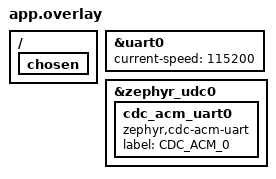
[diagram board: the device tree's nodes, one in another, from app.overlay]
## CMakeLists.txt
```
cmake_minimum_required(VERSION 3.20.0)
find_package(Zephyr REQUIRED HINTS $ENV{ZEPHYR_BASE})
project(nordic_clean)

# Dołączamy nasze pliki źródłowe
target_sources(app PRIVATE 
    src/main.c 
    src/protocol.c
    src/uart_serializer.c
)
```

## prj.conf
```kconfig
CONFIG_GPIO=y
CONFIG_HEAP_MEM_POOL_SIZE=16384
CONFIG_DK_LIBRARY=y

# === Serial & UART ===
CONFIG_SERIAL=y
CONFIG_UART_INTERRUPT_DRIVEN=y
# Wyłączamy Async API na sztywno, żeby uniknąć konfliktów
CONFIG_UART_ASYNC_API=n

# === USB Device Stack ===
CONFIG_USB_DEVICE_STACK=y
CONFIG_USB_DEVICE_PRODUCT="nRF UART3"
CONFIG_USB_DEVICE_VID=0x1915
CONFIG_USB_DEVICE_PID=0x520F
# Ręczna inicjalizacja w main()
CONFIG_USB_DEVICE_INITIALIZE_AT_BOOT=n

# === USB CDC ACM (Kluczowe dla drugiego portu) ===
CONFIG_USB_CDC_ACM=y
CONFIG_UART_LINE_CTRL=y

# === Logowanie (Tylko RTT) ===
CONFIG_LOG=y
CONFIG_USE_SEGGER_RTT=y
CONFIG_LOG_BACKEND_RTT=y
CONFIG_LOG_BACKEND_UART=n
# Wyłączamy konsolę na UART, żeby nie blokowała portu
CONFIG_UART_CONSOLE=n
CONFIG_CONSOLE=y
```

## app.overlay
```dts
/* nordic/app.overlay */
/ {
	chosen {
		/* Usuwamy konsolę z UART0, żeby zwolnić go dla danych */
		/delete-property/ zephyr,console;
		/delete-property/ zephyr,shell-uart;
		/delete-property/ zephyr,uart-mcumgr;
	};
};

/* UART0 - Dane/Ethernet (Górny port J-Link) */
&uart0 {
	status = "okay";
	current-speed = <115200>;
};

/* USB CDC - Konsola Użytkownika (Boczny port nRF USB) */
&zephyr_udc0 {
	cdc_acm_uart0: cdc_acm_uart0 {
		compatible = "zephyr,cdc-acm-uart";
		label = "CDC_ACM_0";
	};
};
```

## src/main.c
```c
#include <zephyr/kernel.h>
#include <zephyr/drivers/uart.h>
#include <zephyr/usb/usb_device.h>
#include <zephyr/logging/log.h>
#include <dk_buttons_and_leds.h>
#include <string.h>
#include "uart_serializer.h" // Tutaj mamy definicje kodów i unpack_header
#include "protocol.h"        // Tutaj mamy definicje InterfaceType

LOG_MODULE_REGISTER(app, LOG_LEVEL_INF);

#define BUF_SIZE 256
#define MSGQ_SIZE 10

// === DEFINICJA STRUKTURY WIADOMOŚCI ===
// Musi być widoczna przed definicją kolejki!
typedef struct {
    uint8_t *data;        // Wskaźnik do dynamicznie alokowanego bufora
    size_t len;           // Długość danych
    InterfaceType source; // Skąd przyszło? (IF_CLI lub IF_UART3)
} PacketMsg;

// UART0 (Górny port) -> DANE (Protokół Binarny)
const struct device *uart_data = DEVICE_DT_GET(DT_NODELABEL(uart0));

// USB CDC (Boczny port) -> KONSOLA (Tekst)
const struct device *uart_cli = DEVICE_DT_GET(DT_NODELABEL(cdc_acm_uart0));

// Definicja kolejki z użyciem naprawionej struktury
K_MSGQ_DEFINE(main_msgq, sizeof(PacketMsg), MSGQ_SIZE, 4);

// Bufor dla Konsoli (Tekst)
static char cli_line_buf[BUF_SIZE];
static int  cli_line_pos = 0;

// === ISR: Konsola (USB - Tekst) ===
static void cli_isr(const struct device *dev, void *user_data) {
    uint8_t c;
    uart_irq_update(dev);
    if (uart_irq_rx_ready(dev)) {
        while (uart_fifo_read(dev, &c, 1) == 1) {
            uart_poll_out(dev, c); // Echo
            if (c == '\n' || c == '\r') {
                if (cli_line_pos > 0) {
                    cli_line_buf[cli_line_pos] = '\0';
                    size_t len;
                    // Serializacja tekstu do binarki
                    uint8_t* pkt = serialize_command_alloc(cli_line_buf, &len);
                    if (pkt) {
                        PacketMsg msg = { .data = pkt, .len = len, .source = IF_CLI };
                        k_msgq_put(&main_msgq, &msg, K_NO_WAIT);
                    } else {
                        uart_poll_out(dev, '?'); uart_poll_out(dev, '\n');
                    }
                    cli_line_pos = 0;
                }
                uart_poll_out(dev, '\r'); uart_poll_out(dev, '\n');
            } else {
                if (cli_line_pos < BUF_SIZE - 1) cli_line_buf[cli_line_pos++] = c;
            }
        }
    }
}
// === ISR: DANE (UART0 - Binarny) ===
static void data_isr(const struct device *dev, void *user_data) {
    uint8_t c;
    
    // Bufor strumieniowy
    static uint8_t rx_buf[256];
    static int rx_pos = 0;
    static uint16_t total_frame_len = 0; // Ile bajtów łącznie musimy uzbierać (Header + Payload)

    uart_irq_update(dev);

    if (uart_irq_rx_ready(dev)) {
        while (uart_fifo_read(dev, &c, 1) == 1) {
            
            // 1. Zbieramy dane do bufora
            if (rx_pos < sizeof(rx_buf)) {
                rx_buf[rx_pos++] = c;
            } else {
                // Przepełnienie - reset
                rx_pos = 0; 
                total_frame_len = 0;
            }

            // 2. Analiza nagłówka (gdy mamy pierwsze 4 bajty)
            if (total_frame_len == 0 && rx_pos >= 4) {
                uint16_t payload_len_from_header;
                uint16_t func_code;
                
                // Odczytujemy to co jest w nagłówku (np. 8)
                unpack_header(rx_buf, &payload_len_from_header, &func_code);
                
                // === KLUCZOWA POPRAWKA ===
                // Protokół mówi: Wartość w nagłówku to PAYLOAD.
                // Więc całkowita długość ramki to: PAYLOAD + 4 BAJTY NAGŁÓWKA.
                total_frame_len = payload_len_from_header + 4;
                
                // Walidacja (czy nie za duże na nasz bufor)
                if (total_frame_len > sizeof(rx_buf) || total_frame_len < 4) {
                    rx_pos = 0; 
                    total_frame_len = 0;
                }
            }

            // 3. Czy mamy całą ramkę?
            if (total_frame_len > 0 && rx_pos >= total_frame_len) {
                // Mamy komplet! (np. 12 bajtów: 4 header + 8 payload)
                
                uint8_t* pkt_copy = k_malloc(total_frame_len);
                if (pkt_copy) {
                    memcpy(pkt_copy, rx_buf, total_frame_len);
                    
                    PacketMsg msg = { 
                        .data = pkt_copy, 
                        .len = total_frame_len, // Przekazujemy CAŁĄ długość ramki
                        .source = IF_UART3 
                    };
                    k_msgq_put(&main_msgq, &msg, K_NO_WAIT);
                }

                // Obsługa sklejonych ramek (jeśli przyszło coś więcej niż ta jedna ramka)
                if (rx_pos > total_frame_len) {
                    int leftover = rx_pos - total_frame_len;
                    memmove(rx_buf, &rx_buf[total_frame_len], leftover);
                    rx_pos = leftover;
                } else {
                    rx_pos = 0;
                }
                total_frame_len = 0; // Reset, czekamy na nowy nagłówek
            }
        }
    }
}

int main(void) {
    k_msleep(100);
    dk_leds_init();

    if (usb_enable(NULL) != 0) { return -1; }
    k_msleep(1000); 

    if (!device_is_ready(uart_data) || !device_is_ready(uart_cli)) return -1;

    // Konfiguracja przerwań
    uart_irq_callback_user_data_set(uart_cli, cli_isr, NULL);
    uart_irq_rx_enable(uart_cli);
    uart_line_ctrl_set(uart_cli, UART_LINE_CTRL_DTR, 1);

    uart_irq_callback_user_data_set(uart_data, data_isr, NULL);
    uart_irq_rx_enable(uart_data);

    LOG_INF("SYSTEM READY");
    LOG_INF(" - CLI (Text/Cmd): USB CDC");
    LOG_INF(" - DATA (Binary): UART0");

    PacketMsg msg;
    for (;;) {
        if (k_msgq_get(&main_msgq, &msg, K_FOREVER) == 0) {
            dk_set_led(DK_LED1, 1);

            if (msg.source == IF_UART3) { 
                // Przyszło z SIECI (UART0)
                uint16_t payload_len, func;
                
                // unpack_header odczyta z bajtów wartość "8"
                unpack_header(msg.data, &payload_len, &func);
                
                LOG_INF("RECV FRAME: HeaderVal=%d, TotalRx=%d, Func=0x%03X", 
                        (int)payload_len, (int)msg.len, func);
                
                // Wypisujemy Payload
                // msg.len to całkowita długość (Header+Payload), np. 12
                // Odejmujemy 4 bajty nagłówka, zostaje 8 bajtów danych.
                size_t actual_payload_len = msg.len - 4;

                if (actual_payload_len > 0) {
                    uint8_t *payload_ptr = msg.data + 4; // Przesuwamy wskaźnik za nagłówek

                    // HEX DUMP
                    LOG_HEXDUMP_INF(payload_ptr, actual_payload_len, "Payload (HEX)");

                    // // STRING VIEW
                    // char txt_buf[129];
                    // size_t print_len = (actual_payload_len < 128) ? actual_payload_len : 128;
                    // memcpy(txt_buf, payload_ptr, print_len);
                    // txt_buf[print_len] = '\0';
                    // LOG_INF("Payload (Str): %s", txt_buf);
                }

                // Echo dla debugu na konsolę CLI
                uart_poll_out(uart_cli, '[');
                uart_poll_out(uart_cli, 'R');
                uart_poll_out(uart_cli, 'X');
                uart_poll_out(uart_cli, ']');
                uart_poll_out(uart_cli, '\r');
                uart_poll_out(uart_cli, '\n');

            } else {
                // Przyszło z KONSOLI -> WYSYŁAMY DO SIECI
                // Uwaga: Tutaj serialize_command_alloc musi też być zgodny z tą logiką!
                // W obecnej wersji serialize_command_alloc wpisuje TOTAL size. 
                // Jeśli chcesz być w 100% zgodny, musisz w uart_serializer.c zmienić:
                // pack_header(..., (uint16_t)payload_size, ...); zamiast total_size.
                
                for(int i=0; i<msg.len; i++) uart_poll_out(uart_data, msg.data[i]);
                LOG_INF("CMD -> NET (%d bytes)", (int)msg.len);
            }

            if (msg.data) k_free(msg.data);
            dk_set_led(DK_LED1, 0);
        }
    }
}
```

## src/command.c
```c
#include "command.h"

void pack_header(uint8_t* buffer, uint16_t length, uint16_t func_code, uint8_t flags) {
    buffer[0] = (length >> 4) & 0xFF;
    buffer[1] = ((length & 0x0F) << 4) | ((func_code >> 8) & 0x0F);
    buffer[2] = func_code & 0xFF;
    buffer[3] = flags;
}

int unpack_header(const uint8_t * buffer, uint16_t * len, uint16_t * func_code, uint8_t * flags)
{
  if(!buffer || !(len || func_code || flags ) ) return -1;
  
  if(len) *len = (uint16_t)(buffer[0]<<4) | (buffer[1] >> 4);
  if(func_code) *func_code = (uint16_t)( (buffer[1] & 0x0F) << 8) | (buffer[2]);
  if(flags) *flags = buffer[3];
  return 0;
}

int parse_line(char *line, Command *cmd) {
    if (line == NULL || cmd == NULL) {
        return 0;
    }

    // 1. Oblicz długość danych
    int len = strlen(line) + 1; // +1 dla null-terminatora

    // 2. Zaalokuj pamięć używając Twojego slab_alloc
    char *payload = (char*)slab_malloc(len);
    
    if (payload == NULL) {
        return 0; // Brak pamięci!
    }

    // 3. Skopiuj dane do nowej pamięci
    strcpy(payload, line);

    // 4. Wypełnij strukturę Command
    cmd->data_ptr = payload;
    cmd->interface = IF_UART; // Oznaczamy, że przyszło z UART

    return 1; // Sukces
}
```

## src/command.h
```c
#ifndef __COMMAND_H
#define __COMMAND_H

#include <stdint.h>
#include <stddef.h>
#include <string.h>
#include "slab_alloc.h"

//source definitions
#define IF_INTERNAL    0x01
#define IF_UART        0x02
#define IF_ETH         0x04
//#define IF_P2P         0x08
//#define IF_BROAD_INNER 0x7F // nearest neighbor broadcast; UART user, P2P and server
//#define IF_BROAD_OUTER 0xFF // every single node in the web, including UART


// --- Command Definitions (Same as before) ---
#define CAT_SYSTEM    0x1
#define CAT_SIM       0x2
#define CAT_SIM_API   0x3
#define CAT_SIM_NOTIF 0xE
#define CAT_SYS_NOTIF 0xF





/*
  
 OUTPUTS  

*/


// System commands
#define SYS_PING     0x01 //payload: str(ip)
#define SYS_CONN     0x02 //payload: str(ip)
#define SYS_DISCONN  0x03 //payload: None
#define SYS_RAW_SEND 0x04 //payload: str(any)



// System Notifications (0xF)
#define SYS_NOTIF_UNKNOWN 0x01 //payload: None
#define SYS_NOTIF_DEBUG   0x02 //payload: str(any)
#define SYS_NOTIF_FORBID  0x03 //payload: None
#define SYS_NOTIF_OK      0x04 //payload: None

// Simulation Notifications (0xE)
#define NOTIF_SIM_ALERT   0x01 // Code Payload
#define NOTIF_SIM_LOG     0x02 // String Payload







typedef struct {
  uint8_t interface; //source or target, depending on where it is fed
  uint8_t * data_ptr; //typically a pointer to a slab
} Command;



void pack_header(uint8_t* buffer, uint16_t length, uint16_t func_code, uint8_t flags);
int unpack_header(const uint8_t * buffer, uint16_t * len, uint16_t * func_code, uint8_t * flags);
int parse_line(char *line, Command *cmd);


#endif
```

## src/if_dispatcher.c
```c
#include "if_dispatcher.h"

// --- Zmienna globalna (Naprawia błąd: out_queue undeclared) ---
static osMessageQueueId_t out_queue = NULL; 

// --- Worker ---
__NO_RETURN static void dispatcher_worker(void *argument)
{
  for(;;)
  {
    Command cmd;
    // Pobieramy komendę z kolejki
    osStatus_t status = osMessageQueueGet(out_queue, &cmd, NULL, osWaitForever);

    if (status == osOK) {
        if(cmd.interface & IF_UART)
        {
          uint8_t buffer[128];
          
          // Serializacja komendy do bufora
          int len = uart_serialize(&cmd, buffer, sizeof(buffer));

          if(len > 0) {
              if (len < 128) buffer[len] = 0; // Null-terminator dla bezpieczeństwa
              
              osStatus_t result = uart_printn((char*)buffer);
              
              if(result != osOK) {
                   // Opcjonalnie obsługa błędu
              }
          } else {
               uart_printn("!ERR serialize fail\r\n");
          }
        }
        
        // Zwalniamy pamięć alokowaną dla danych komendy
        if (cmd.data_ptr) {
            slab_free(cmd.data_ptr);
        }
    }
  }
}

// --- Funkcje Publiczne ---

osStatus_t init_if_dispatcher(osMessageQueueId_t out_q)
{
    out_queue = out_q; // Przypisanie do zmiennej globalnej

    osThreadAttr_t worker_attr = {
        .name = "if_dispatch",
        .priority = osPriorityNormal,
        .stack_size = 1024
    };

    // Użycie funkcji dispatcher_worker (Naprawia błąd: defined but not used)
    if (osThreadNew(dispatcher_worker, NULL, &worker_attr) == NULL) {
        return osError;
    }

    return osOK;
}

osStatus_t tick_dispatcher(osMessageQueueId_t out_q)
{
    // Funkcja cykliczna (jeśli potrzebna w main loop)
    return osOK;
}
```

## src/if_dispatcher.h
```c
#ifndef __IF_DISPATCHER_H
#define __IF_DISPATCHER_H

#include <cmsis_os2.h>            // ::CMSIS:RTOS2
#include "uart_serializer.h"
#include "uart_handle.h"
#include "slab_alloc.h"
#include "command.h"
#include <string.h> 


osStatus_t init_if_dispatcher(osMessageQueueId_t out_q);


osStatus_t tick_dispatcher(osMessageQueueId_t out_q);

#endif
```

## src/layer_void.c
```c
/* src/layer_void.c - Zaślepka */
#include "layer_void.h"


void process_request_void(void *arg) {
    // Pusta funkcja - brak obsługi sieci w tej wersji
}
```

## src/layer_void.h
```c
#ifndef __LAYER_VOID_H
#define __LAYER_VOID_H

#include "command.h"
#include "slab_alloc.h"

#include <cmsis_os2.h>



osStatus_t init_pipeline(osMessageQueueId_t in_q, osMessageQueueId_t out_q);



#endif
```

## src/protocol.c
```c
#include <zephyr/kernel.h>
#include <string.h>
#include <stdlib.h>
#include <stdio.h>
#include "protocol.h"


static int parse_ip_str(const char *ip_str, uint8_t *out_ip) {
    int values[4];
    if (sscanf(ip_str, "%d.%d.%d.%d", &values[0], &values[1], &values[2], &values[3]) != 4) return -1;
    for(int i=0; i<4; i++) out_ip[i] = (uint8_t)values[i];
    return 0;
}
static void pack_header(uint8_t* buf, uint16_t total_len, uint16_t func_code) {
    buf[0] = (total_len >> 4) & 0xFF;
    buf[1] = ((total_len & 0x0F) << 4) | ((func_code >> 8) & 0x0F);
    buf[2] = func_code & 0xFF;
    buf[3] = 0x00;
}

int parse_text_command(char *text, ProtocolMsg *out_msg) {
    char *saveptr;
    char cmd_buf[128]; 
    strncpy(cmd_buf, text, sizeof(cmd_buf)-1);
    cmd_buf[sizeof(cmd_buf)-1] = '\0';

    char *token = strtok_r(cmd_buf, " \r\n", &saveptr);
    if (!token) return -1;

    // Domyślnie odpowiedź trafia na CLI, chyba że zmienimy na UART3
    out_msg->target_if = IF_CLI; 

    if (strcmp(token, "neighbor") == 0) {
        char *subcmd = strtok_r(NULL, " \r\n", &saveptr);
        if (!subcmd) return -1;

        if (strcmp(subcmd, "ping") == 0) {
             // Ping akurat w Twoim starym kodzie szedł na UART, 
             // ale możemy go wysłać na UART3 jeśli to test łącza.
             // Zostawmy na razie na CLI (jako echo) lub UART3 wedle uznania.
             // W LPC ping był "lokalny".
             char *ip = strtok_r(NULL, " \r\n", &saveptr);
             if (!ip) return -1;
             out_msg->func_code = (CAT_SYSTEM << 8) | SYS_PING;
             out_msg->payload_len = strlen(ip) + 1;
             out_msg->payload = k_malloc(out_msg->payload_len);
             strcpy(out_msg->payload, ip);
             return 0;
        }
        else if (strcmp(subcmd, "connect") == 0) {
            // CONNECT -> Logika połączenia idzie na UART3
            char *ip = strtok_r(NULL, " \r\n", &saveptr);
            char *port_str = strtok_r(NULL, " \r\n", &saveptr);
            if (!ip || !port_str) return -1;

            uint8_t ip_bytes[4];
            if (parse_ip_str(ip, ip_bytes) != 0) return -2;
            int port = atoi(port_str);

            out_msg->func_code = (CAT_SYSTEM << 8) | SYS_CONN;
            out_msg->payload_len = 6;
            out_msg->payload = k_malloc(6);
            memcpy(out_msg->payload, ip_bytes, 4);
            out_msg->payload[4] = (port >> 8) & 0xFF;
            out_msg->payload[5] = port & 0xFF;
            
            out_msg->target_if = IF_UART3; // Kierujemy do UART3
            return 0;
        }
        else if (strcmp(subcmd, "disconnect") == 0) {
            out_msg->func_code = (CAT_SYSTEM << 8) | SYS_DISCONN;
            out_msg->payload_len = 0;
            out_msg->payload = NULL;
            out_msg->target_if = IF_UART3; // Kierujemy do UART3
            return 0;
        }
        else if (strcmp(subcmd, "send") == 0) {
            // SEND -> Dane lecą na UART3
            char *msg = strtok_r(NULL, "\r\n", &saveptr);
            if (!msg) return -1;

            out_msg->func_code = (CAT_SYSTEM << 8) | SYS_RAW_SEND;
            out_msg->payload_len = strlen(msg) + 1;
            out_msg->payload = k_malloc(out_msg->payload_len);
            strcpy(out_msg->payload, msg);
            
            out_msg->target_if = IF_UART3; // Kierujemy do UART3
            return 0;
        }
    }
    return -1;
}

int serialize_message(ProtocolMsg *msg, uint8_t *buffer, size_t max_len) {
    size_t total_len = 4 + msg->payload_len;
    if (total_len > max_len) return -2;
    pack_header(buffer, (uint16_t)total_len, msg->func_code);
    if (msg->payload && msg->payload_len > 0) {
        memcpy(buffer + 4, msg->payload, msg->payload_len);
    }
    return total_len;
}

void free_protocol_msg(ProtocolMsg *msg) {
    if (msg->payload) {
        k_free(msg->payload);
        msg->payload = NULL;
    }
}
```

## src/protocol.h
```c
#ifndef PROTOCOL_H
#define PROTOCOL_H

#include <stdint.h>
#include <stddef.h>

// Kody funkcji (bez zmian)
#define CAT_SYSTEM      0x0F
#define SYS_PING        0x01
#define SYS_CONN        0x02
#define SYS_DISCONN     0x03
#define SYS_RAW_SEND    0x04

// Definicja interfejsów
typedef enum {
    IF_CLI   = 0, // Konsola sterująca
    IF_UART3 = 1, // Kanał danych (funkcjonalny odpowiednik ETH)
} InterfaceType;

typedef struct {
    uint16_t func_code;
    InterfaceType target_if; 
    uint8_t *payload;
    size_t payload_len;
} ProtocolMsg;

int parse_text_command(char *text, ProtocolMsg *out_msg);
int serialize_message(ProtocolMsg *msg, uint8_t *buffer, size_t max_len);
void free_protocol_msg(ProtocolMsg *msg);

#endif
```

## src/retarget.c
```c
#define __FILE_INCOMPLETE 1
#include <stdio.h>

#include "uart_handle.h"

//warning - it blocks! incredibly costly

int stdout_putchar(int ch, FILE *f)
{

  uart2_putc_sys(ch);
  return ch;
}


int stderr_putchar(int ch, FILE *f)
{

  stdout_putchar(ch, f);
  return ch;
}

/*

//#include <rt_sys.h> // Include this for standard definitions
//#include <rt_misc.h>

// 1. Disable Semihosting 
#if defined(__ARMCC_VERSION) && (__ARMCC_VERSION >= 6010050)
    __asm(".global __use_no_semihosting\n\t");
#else
    #pragma import(__use_no_semihosting)
#endif



struct __FILE { int handle; };
FILE __stdout;
FILE __stdin;

int fputc(int ch, FILE *f)
{

  uart2_putc_sys(ch);
  return ch;
}

int __write(int handle, const unsigned char *buf, unsigned len)
{
    (void)handle;

    for (unsigned i = 0; i < len; i++)
        uart2_putc_sys(buf[i]);

    return len;
}

int ferror(FILE *f)
{

  return EOF;
}

void _ttywrch(int ch)
{
  uart2_putc_sys(ch);
}



void _sys_exit(int return_code) {
    while (1); // Infinite loop on exit
}

void test(void)
{
  printf("Hello world\n");
}*/
```

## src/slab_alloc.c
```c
#include "slab_alloc.h"



// Alignment ensures these buffers can hold structs safely
#define ALIGNMENT _Alignas(16) 

// --- Static Storage ---

/*ALIGNMENT*/ static uint8_t pool_32[COUNT_32][SIZE_32];
/*ALIGNMENT*/ static uint8_t pool_128[COUNT_128][SIZE_128];
/*ALIGNMENT*/ static uint8_t pool_512[COUNT_512][SIZE_512];
/*ALIGNMENT*/ static uint8_t pool_2k[COUNT_2K][SIZE_2K];

// --- Availability Flags (1 = Used, 0 = Free) ---

static uint32_t flags_32 = 0;
static uint32_t flags_128 = 0;
static uint32_t flags_512 = 0;
static uint32_t flags_2k = 0;



static osMutexId_t slab_mutex_id;
// Reserve static memory for the Mutex Control Block.
// Must be 64-bit aligned on Cortex-M3 to avoid Usage Faults.
/*ALIGNMENT*/ static uint64_t slab_mutex_cb[8]; 

static const osMutexAttr_t slab_mutex_attr = {
    .name = "SlabAllocatorMutex",
    // CRITICAL: Priority Inheritance prevents high-priority tasks from
    // blocking on this allocator if a low-priority task is preempted.
    .attr_bits = osMutexPrioInherit, 
    .cb_mem = &slab_mutex_cb,
    .cb_size = sizeof(slab_mutex_cb)
};



void slab_init(void) {
    slab_mutex_id = osMutexNew(&slab_mutex_attr);
    // Note: If using RTX5, ensure osKernelInitialize() is called before this.
}



// --- Helper Functions ---

// Returns index of first 0 bit, or -1 if all are 1
static int find_free_index(uint32_t mask, int max_count) {
  
  if(mask == 0xFFFFFFFF) return -1; //optimization
  
    for (int i = 0; i < max_count; i++) {
        if (!((mask >> i) & 1)) {
            return i;
        }
    }
    return -1;
}



/**
  * @brief Finds the first free bit (0) using Cortex-M3 hardware instructions.
 * @return Index (0-31) or -1 if full.
 *//*
__STATIC_FORCEINLINE int find_free_index(uint32_t mask, int max_count) {
    // 1. Invert mask: We are looking for a '0' in the original, 
    //    so we look for a '1' in the inverted value.
    uint32_t free_bits = ~mask;

    // 2. Check if pool is totally full (no 1s left)
    if ((free_bits & ((1ULL << max_count) - 1)) == 0) {
        return -1;
    }

    // 3. Cortex-M3 Optimization:
    // __RBIT reverses bits (MSB <-> LSB).
    // __CLZ counts leading zeros.
    // This combination effectively finds the index of the Least Significant Set Bit (CTZ).
    // Example: 00...0100 (Index 2) -> RBIT -> 0010...00 -> CLZ -> 2.
    return __CLZ(__RBIT(free_bits));
}
*/









static void set_flag(uint32_t *mask, int index, int used) {
    if (used) *mask |= (1U << index);
    else      *mask &= ~(1U << index);
}


// --- Public API ---

void* slab_malloc(size_t size) {
    if (size == 0 || size > 2048) return NULL;

    int start_tier = 0;
    if (size > 512) start_tier = 3;
    else if (size > 128) start_tier = 2;
    else if (size > 32)  start_tier = 1;

    void* ptr = NULL;

    // Acquire Mutex (Waits forever, Priority Inherited)
    osStatus_t status = osMutexAcquire(slab_mutex_id, osWaitForever);
    if (status != osOK) return NULL;

    // Cascade / Fallback Search
    for (int tier = start_tier; tier <= 3; tier++) {
        int index = -1;

        switch (tier) {
            case 0: // 32 Bytes
                index = find_free_index(flags_32, COUNT_32);
                if (index != -1) {
                    set_flag(&flags_32, index, 1);
                    ptr = &pool_32[index][0];
                }
                break;
            case 1: // 128 Bytes
                index = find_free_index(flags_128, COUNT_128);
                if (index != -1) {
                    set_flag(&flags_128, index, 1);
                    ptr = &pool_128[index][0];
                }
                break;
            case 2: // 512 Bytes
                index = find_free_index(flags_512, COUNT_512);
                if (index != -1) {
                    set_flag(&flags_512, index, 1);
                    ptr = &pool_512[index][0];
                }
                break;
            case 3: // 2048 Bytes
                index = find_free_index(flags_2k, COUNT_2K);
                if (index != -1) {
                    set_flag(&flags_2k, index, 1);
                    ptr = &pool_2k[index][0];
                }
                break;
        }

        if (ptr != NULL) break;
    }

    osMutexRelease(slab_mutex_id);
    return ptr;
}

void* slab_calloc(size_t num, size_t size) {
    size_t total_size = num * size;
    if (num != 0 && total_size / num != size) return NULL; // Overflow check

    void* ptr = slab_malloc(total_size);
    if (ptr) {
        memset(ptr, 0, total_size);
    }
    return ptr;
}

void slab_free(void* ptr) {
    if (!ptr) return;
    uintptr_t p_addr = (uintptr_t)ptr;

    uint32_t* target_flags = NULL;
    int target_index = -1;

    // Address arithmetic does NOT require lock (Read-Only static constants)
    if (p_addr >= (uintptr_t)pool_32 && p_addr < (uintptr_t)pool_32 + sizeof(pool_32)) {
        size_t offset = p_addr - (uintptr_t)pool_32;
        if (offset % SIZE_32 == 0) {
            target_flags = &flags_32;
            target_index = offset / SIZE_32;
        }
    }
    else if (p_addr >= (uintptr_t)pool_128 && p_addr < (uintptr_t)pool_128 + sizeof(pool_128)) {
        size_t offset = p_addr - (uintptr_t)pool_128;
        if (offset % SIZE_128 == 0) {
            target_flags = &flags_128;
            target_index = offset / SIZE_128;
        }
    }
    else if (p_addr >= (uintptr_t)pool_512 && p_addr < (uintptr_t)pool_512 + sizeof(pool_512)) {
        size_t offset = p_addr - (uintptr_t)pool_512;
        if (offset % SIZE_512 == 0) {
            target_flags = &flags_512;
            target_index = offset / SIZE_512;
        }
    }
    else if (p_addr >= (uintptr_t)pool_2k && p_addr < (uintptr_t)pool_2k + sizeof(pool_2k)) {
        size_t offset = p_addr - (uintptr_t)pool_2k;
        if (offset % SIZE_2K == 0) {
            target_flags = &flags_2k;
            target_index = offset / SIZE_2K;
        }
    }

    if (target_flags != NULL && target_index != -1) {
        osMutexAcquire(slab_mutex_id, osWaitForever);
        set_flag(target_flags, target_index, 0);
        osMutexRelease(slab_mutex_id);
    }
}
```

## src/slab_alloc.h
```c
#ifndef __SLAB_ALLOC_H
#define __SLAB_ALLOC_H

#include <stdio.h>
#include <stdint.h>
#include <stddef.h>
#include <string.h>
#include <cmsis_os2.h>                // ::CMSIS:RTOS2

// --- Configuration ---

//buffer sizes
#define SIZE_32    32
#define SIZE_128   128
#define SIZE_512   512
#define SIZE_2K    2048


//buffer counts (max 32)
#define COUNT_32   32
#define COUNT_128  8
#define COUNT_512  4
#define COUNT_2K   2





// --- Public API ---

void slab_init(void);

void* slab_malloc(size_t size);
void* slab_calloc(size_t num, size_t size);
void slab_free(void* ptr);




#endif
```

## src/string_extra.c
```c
#include "string_extra.h"

#define false 0
#define true 1
#define bool int
  




char* itoa_dec(int num, char* str) {
    int i = 0;
    bool is_negative = false;

    // Handle 0 explicitly
    if (num == 0) {
        str[i++] = '0';
        str[i] = '\0';
        return str;
    }

    // Handle negative numbers
    if (num < 0) {
        is_negative = true;
        num = -num;
    }

    // Extract digits (in reverse order)
    while (num != 0) {
        int digit = num % 10;
        str[i++] = digit + '0';
        num /= 10;
    }

    // Add minus sign if needed
    if (is_negative)
        str[i++] = '-';

    str[i] = '\0';

    // Reverse the string
    int start = 0;
    int end = i - 1;
    while (start < end) {
        char tmp = str[start];
        str[start] = str[end];
        str[end] = tmp;
        start++;
        end--;
    }

    return str;
}


char* itoa_hex(int num, char* str) {
    const char hex_chars[] = "0123456789ABCDEF";
    unsigned int n = (unsigned int)num; // treat as unsigned
    char buf[9]; // enough for 8 hex digits + null
    int i = 0;

    if (str == 0) return 0;

    // Handle zero explicitly
    if (n == 0) {
        str[0] = '0';
        str[1] = '\0';
        return str;
    }

    // Convert to hex in reverse order
    while (n != 0 && i < 8) {
        buf[i++] = hex_chars[n & 0xF];
        n >>= 4;
    }

    // Reverse the string into output buffer
    int j;
    for (j = 0; j < i; j++) {
        str[j] = buf[i - j - 1];
    }
    str[i] = '\0';
    return str;
}


char * itoa(int num, char* str, int base)
{
switch(base)
  {
  case 10:
    return itoa_dec(num, str);
  case 16:
    return itoa_hex(num, str);
  default:
    return 0;
  }
}
```
